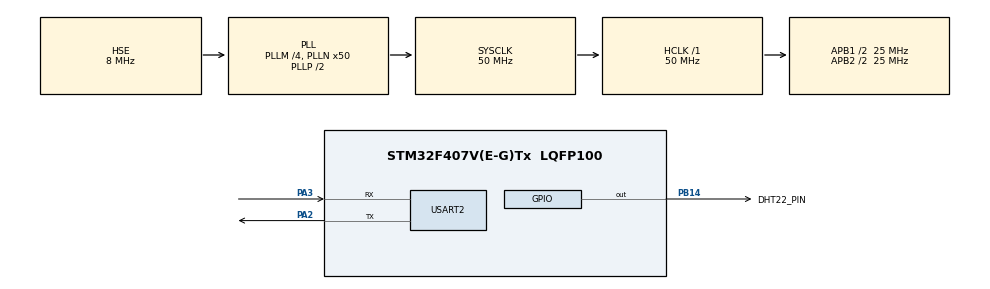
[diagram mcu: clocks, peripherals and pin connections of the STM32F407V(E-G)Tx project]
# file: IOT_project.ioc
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Mcu.Family=STM32F4
Mcu.Name=STM32F407V(E-G)Tx
Mcu.Package=LQFP100
NVIC.PriorityGroup=NVIC_PRIORITYGROUP_0
PA2.Mode=Asynchronous
PA2.Signal=USART2_TX
PA3.Mode=Asynchronous
PA3.Signal=USART2_RX
PB14.GPIO_Label=DHT22_PIN
PB14.GPIO_PuPd=GPIO_PULLUP
PB14.Signal=GPIO_Output
PH0-OSC_IN.Mode=HSE-External-Oscillator
PH0-OSC_IN.Signal=RCC_OSC_IN
PH1-OSC_OUT.Mode=HSE-External-Oscillator
PH1-OSC_OUT.Signal=RCC_OSC_OUT
ProjectManager.HeapSize=0x200
ProjectManager.StackSize=0x400
ProjectManager.TargetToolchain=STM32CubeIDE
RCC.48MHZClocksFreq_Value=14285714.285714285
RCC.AHBFreq_Value=50000000
RCC.APB1CLKDivider=RCC_HCLK_DIV2
RCC.APB1Freq_Value=25000000
RCC.APB1TimFreq_Value=50000000
RCC.APB2CLKDivider=RCC_HCLK_DIV2
RCC.APB2Freq_Value=25000000
RCC.APB2TimFreq_Value=50000000
RCC.CortexFreq_Value=50000000
RCC.HCLKFreq_Value=50000000
RCC.HSE_VALUE=8000000
RCC.HSI_VALUE=16000000
RCC.LSE_VALUE=32768
RCC.PLLM=4
RCC.PLLN=50
RCC.PLLQ=7
RCC.PLLSourceVirtual=RCC_PLLSOURCE_HSE
RCC.SYSCLKFreq_VALUE=50000000
RCC.SYSCLKSource=RCC_SYSCLKSOURCE_PLLCLK
RCC.VCOOutputFreq_Value=100000000
TIM6.Period=0xffff-1
TIM6.Prescaler=50-1
USART2.VirtualMode=VM_ASYNC
VP_TIM6_VS_ClockSourceINT.Mode=Enable_Timer
board=STM32F407G-DISC1

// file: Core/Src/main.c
/* USER CODE BEGIN Header */
/**
  ******************************************************************************
  * @file           : main.c
  * @brief          : Main program body
  ******************************************************************************
  * @attention
  *
  * Copyright (c) 2024 STMicroelectronics.
  * All rights reserved.
  *
  * This software is licensed under terms that can be found in the LICENSE file
  * in the root directory of this software component.
  * If no LICENSE file comes with this software, it is provided AS-IS.
  *
  ******************************************************************************
  */
/* USER CODE END Header */
#include "main.h"
#include<stdio.h>
#include<string.h>

/* USER CODE BEGIN PD */
#define UART_BUFFER_SIZE 100

/* USER CODE END PD */

TIM_HandleTypeDef htim6;

UART_HandleTypeDef huart2;

/* USER CODE BEGIN PV */
char uart_tx_buffer[UART_BUFFER_SIZE];
char uart_rx_buffer[UART_BUFFER_SIZE];

/* USER CODE END PV */

void SystemClock_Config(void);
static void MX_GPIO_Init(void);
static void MX_TIM6_Init(void);
static void MX_USART2_UART_Init(void);
/* USER CODE BEGIN PFP */
uint8_t DHT22_Start (void);
uint8_t DHT22_Read (void);
void delay (uint16_t time);

void sendATCommand(const char *command);
void sendSSIDAndPassword(const char *ssid, const char *password);
void sendData(const char *apiKey, const char *fieldData);
/* USER CODE END PFP */

/* USER CODE BEGIN 0 */
uint8_t  Presence,Rh_byte1,Rh_byte2,Temp_byte1,Temp_byte2,SUM;
float Humidity,Temperature;
/* USER CODE END 0 */

int main(void)
{
  /* USER CODE BEGIN 1 */

uint16_t TEMP,RH;

  /* USER CODE END 1 */

  /* MCU Configuration--------------------------------------------------------*/

  /* Reset of all peripherals, Initializes the Flash interface and the Systick. */
  HAL_Init();

  /* Configure the system clock */
  SystemClock_Config();

  /* Initialize all configured peripherals */
  MX_GPIO_Init();
  MX_TIM6_Init();
  MX_USART2_UART_Init();
  /* USER CODE BEGIN 2 */
  HAL_TIM_Base_Start(&htim6);

  const char *ssid = "your_ssid";
  const char *password = "put_your_password";
  const char *apiKey = "7W362EETBWTU2K7S";
  char fieldData[50];

  // Reset ESP32
  sendATCommand("AT+RST\r\n");
  HAL_Delay(2000);

  // Check if ESP is ready
  sendATCommand("AT\r\n");
  HAL_Delay(1000);

  // Set Wi-Fi mode to Station
  sendATCommand("AT+CWDHCP_CUR=1,1");
  sendATCommand("AT+CWMODE=1\r\n");
  HAL_Delay(1000);

  // Send SSID and Password
  sendSSIDAndPassword(ssid, password);
  HAL_Delay(5000);
  sendData(apiKey, fieldData);

  /* USER CODE END 2 */

  /* Infinite loop */
  /* USER CODE BEGIN WHILE */
  while (1)
  {
	  Presence = DHT22_Start();
	  Rh_byte1 = DHT22_Read ();
	  Rh_byte2 = DHT22_Read ();
      Temp_byte1 = DHT22_Read ();
      Temp_byte2 = DHT22_Read ();
      SUM = DHT22_Read();
	  TEMP = ((Temp_byte1<<8)|Temp_byte2);
	  RH = ((Rh_byte1<<8)|Rh_byte2);
	  Temperature = (float) (TEMP/10.0);
	  Humidity = (float) (RH/10.0);
	  sprintf(fieldData,"field1=%.2f&field2=%.2f",Temperature,Humidity);
	  sendData(apiKey, fieldData);
	  HAL_Delay(2000);
    /* USER CODE END WHILE */

  }
}

void SystemClock_Config(void)
{
  RCC_OscInitTypeDef RCC_OscInitStruct = {0};
  RCC_ClkInitTypeDef RCC_ClkInitStruct = {0};

  /** Configure the main internal regulator output voltage
  */
  __HAL_RCC_PWR_CLK_ENABLE();
  __HAL_PWR_VOLTAGESCALING_CONFIG(PWR_REGULATOR_VOLTAGE_SCALE1);

  /** Initializes the RCC Oscillators according to the specified parameters
  * in the RCC_OscInitTypeDef structure.
  */
  RCC_OscInitStruct.OscillatorType = RCC_OSCILLATORTYPE_HSE;
  RCC_OscInitStruct.HSEState = RCC_HSE_ON;
  RCC_OscInitStruct.PLL.PLLState = RCC_PLL_ON;
  RCC_OscInitStruct.PLL.PLLSource = RCC_PLLSOURCE_HSE;
  RCC_OscInitStruct.PLL.PLLM = 4;
  RCC_OscInitStruct.PLL.PLLN = 50;
  RCC_OscInitStruct.PLL.PLLP = RCC_PLLP_DIV2;
  RCC_OscInitStruct.PLL.PLLQ = 7;
  if (HAL_RCC_OscConfig(&RCC_OscInitStruct) != HAL_OK)
  {
    Error_Handler();
  }

  /** Initializes the CPU, AHB and APB buses clocks
  */
  RCC_ClkInitStruct.ClockType = RCC_CLOCKTYPE_HCLK|RCC_CLOCKTYPE_SYSCLK
                              |RCC_CLOCKTYPE_PCLK1|RCC_CLOCKTYPE_PCLK2;
  RCC_ClkInitStruct.SYSCLKSource = RCC_SYSCLKSOURCE_PLLCLK;
  RCC_ClkInitStruct.AHBCLKDivider = RCC_SYSCLK_DIV1;
  RCC_ClkInitStruct.APB1CLKDivider = RCC_HCLK_DIV2;
  RCC_ClkInitStruct.APB2CLKDivider = RCC_HCLK_DIV2;

  if (HAL_RCC_ClockConfig(&RCC_ClkInitStruct, FLASH_LATENCY_1) != HAL_OK)
  {
    Error_Handler();
  }
}

static void MX_TIM6_Init(void)
{

  TIM_MasterConfigTypeDef sMasterConfig = {0};

  htim6.Instance = TIM6;
  htim6.Init.Prescaler = 50-1;
  htim6.Init.CounterMode = TIM_COUNTERMODE_UP;
  htim6.Init.Period = 0xffff-1;
  htim6.Init.AutoReloadPreload = TIM_AUTORELOAD_PRELOAD_DISABLE;
  if (HAL_TIM_Base_Init(&htim6) != HAL_OK)
  {
    Error_Handler();
  }
  sMasterConfig.MasterOutputTrigger = TIM_TRGO_RESET;
  sMasterConfig.MasterSlaveMode = TIM_MASTERSLAVEMODE_DISABLE;
  if (HAL_TIMEx_MasterConfigSynchronization(&htim6, &sMasterConfig) != HAL_OK)
  {
    Error_Handler();
  }

}

static void MX_USART2_UART_Init(void)
{

  huart2.Instance = USART2;
  huart2.Init.BaudRate = 115200;
  huart2.Init.WordLength = UART_WORDLENGTH_8B;
  huart2.Init.StopBits = UART_STOPBITS_1;
  huart2.Init.Parity = UART_PARITY_NONE;
  huart2.Init.Mode = UART_MODE_TX_RX;
  huart2.Init.HwFlowCtl = UART_HWCONTROL_NONE;
  huart2.Init.OverSampling = UART_OVERSAMPLING_16;
  if (HAL_UART_Init(&huart2) != HAL_OK)
  {
    Error_Handler();
  }

}

static void MX_GPIO_Init(void)
{
  GPIO_InitTypeDef GPIO_InitStruct = {0};

  /* GPIO Ports Clock Enable */
  __HAL_RCC_GPIOH_CLK_ENABLE();
  __HAL_RCC_GPIOA_CLK_ENABLE();
  __HAL_RCC_GPIOB_CLK_ENABLE();

  /*Configure GPIO pin Output Level */
  HAL_GPIO_WritePin(DHT22_PIN_GPIO_Port, DHT22_PIN_Pin, GPIO_PIN_RESET);

  /*Configure GPIO pin : DHT22_PIN_Pin */
  GPIO_InitStruct.Pin = DHT22_PIN_Pin;
  GPIO_InitStruct.Mode = GPIO_MODE_OUTPUT_PP;
  GPIO_InitStruct.Pull = GPIO_PULLUP;
  GPIO_InitStruct.Speed = GPIO_SPEED_FREQ_LOW;
  HAL_GPIO_Init(DHT22_PIN_GPIO_Port, &GPIO_InitStruct);

}

/* USER CODE BEGIN 4 */

uint8_t DHT22_Start (void)
{
	GPIO_InitTypeDef GPIO_InitStructPrivate = {0};
	GPIO_InitStructPrivate.Pin = DHT22_PIN_Pin;
	GPIO_InitStructPrivate.Mode = GPIO_MODE_OUTPUT_PP;
	GPIO_InitStructPrivate.Speed = GPIO_SPEED_FREQ_LOW;
	GPIO_InitStructPrivate.Pull = GPIO_NOPULL;
	HAL_GPIO_Init(DHT22_PIN_GPIO_Port, &GPIO_InitStructPrivate);  // set the pin as output
	HAL_GPIO_WritePin (DHT22_PIN_GPIO_Port, DHT22_PIN_Pin, 0);   // pull the pin low
	HAL_Delay(1200);   // wait for > 1ms

	HAL_GPIO_WritePin (DHT22_PIN_GPIO_Port, DHT22_PIN_Pin, 1);   // pull the pin high
	delay (30);   // wait for 30us

	GPIO_InitStructPrivate.Mode = GPIO_MODE_INPUT;
	GPIO_InitStructPrivate.Pull = GPIO_PULLUP;
	HAL_GPIO_Init(DHT22_PIN_GPIO_Port, &GPIO_InitStructPrivate); // set the pin as input

	delay (40);  // wait for 40us
	uint8_t Response = 0;
	if (!(HAL_GPIO_ReadPin (DHT22_PIN_GPIO_Port, DHT22_PIN_Pin))) // if the pin is low
	{
		delay (80);   // wait for 80us

	  if ((HAL_GPIO_ReadPin (DHT22_PIN_GPIO_Port, DHT22_PIN_Pin))) Response = 1;  // if the pin is high, response is ok

	  else Response = -1;
	}

	while ((HAL_GPIO_ReadPin (DHT22_PIN_GPIO_Port, DHT22_PIN_Pin))); // wait for the pin to go low

	return Response;
}
uint8_t DHT22_Read (void)
{
	uint8_t i,j;
	for (j=0;j<8;j++)
	{
		while (!(HAL_GPIO_ReadPin (DHT22_PIN_GPIO_Port, DHT22_PIN_Pin)));   // wait for the pin to go high
		delay (40);   // wait for 40 us

		if (!(HAL_GPIO_ReadPin (DHT22_PIN_GPIO_Port, DHT22_PIN_Pin)))   // if the pin is low
		{
			i&= ~(1<<(7-j));   // write 0
		}
		else i|= (1<<(7-j));  // if the pin is high, write 1
		while ((HAL_GPIO_ReadPin (DHT22_PIN_GPIO_Port, DHT22_PIN_Pin)));  // wait for the pin to go low
	}

	return i;
}
void delay (uint16_t time)
{
	/* delay in microseconds */
	__HAL_TIM_SET_COUNTER(&htim6, 0);
	while ((__HAL_TIM_GET_COUNTER(&htim6))<time);
}

void sendATCommand(const char *command) {
    HAL_UART_Transmit(&huart2, (uint8_t *)command, sizeof(command), HAL_MAX_DELAY);
}

void sendSSIDAndPassword(const char *ssid, const char *password) {
    HAL_UART_Transmit(&huart2, (uint8_t *)"AT+CWJAP=\"", 11, HAL_MAX_DELAY);
    HAL_UART_Transmit(&huart2, (uint8_t *)ssid,sizeof(ssid), HAL_MAX_DELAY);
    HAL_UART_Transmit(&huart2, (uint8_t *)"\",\"", 3, HAL_MAX_DELAY);
    HAL_UART_Transmit(&huart2, (uint8_t *)password,sizeof(password), HAL_MAX_DELAY);
    HAL_UART_Transmit(&huart2, (uint8_t *)"\"\r\n", 4, HAL_MAX_DELAY);
}
void sendData(const char *apiKey, const char *fieldData){
    sendATCommand("AT+CIPSTART=\"TCP\",\"api.thingspeak.com\",80\r\n");
    HAL_Delay(2000);

    char httpRequest[100];
    sprintf(httpRequest, "GET https://api.thingspeak.com/update?api_key=%s&%s ", apiKey, fieldData);
    char cmd[50];
    sprintf(cmd, "AT+CIPSEND=%d\r\n", strlen(httpRequest));
    sendATCommand(cmd);
    HAL_Delay(1000);

    sendATCommand(httpRequest);
    HAL_Delay(2000);

    sendATCommand("AT+CIPCLOSE\r\n");
}

/* USER CODE END 4 */

void Error_Handler(void)
{
  __disable_irq();
  while (1)
  {
  }
}
